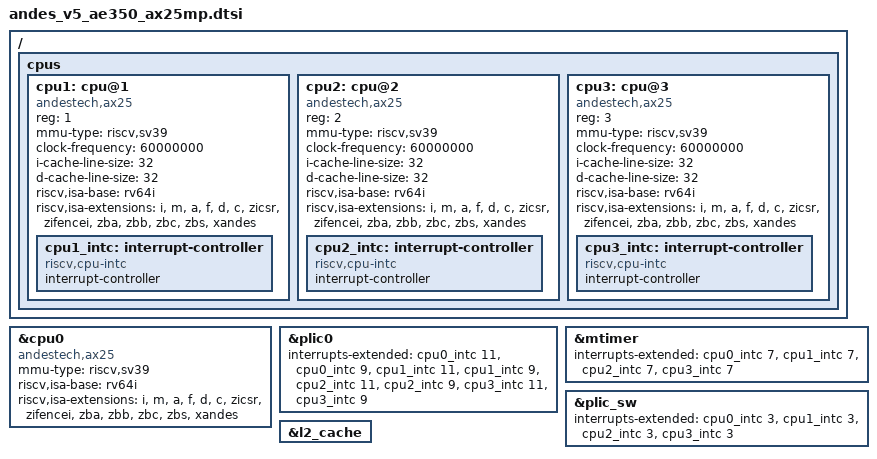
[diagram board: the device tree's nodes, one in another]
/*
 * Copyright (c) 2026 Andes Technology Corporation
 *
 * SPDX-License-Identifier: Apache-2.0
 */

#include <riscv/andes/andes_v5_ae350.dtsi>

/ {
	cpus {
		cpu1: cpu@1 {
			compatible = "andestech,ax25", "andestech,andescore-v5", "riscv";
			reg = <1>;
			device_type = "cpu";
			mmu-type = "riscv,sv39";
			clock-frequency = <60000000>;
			i-cache-line-size = <32>;
			d-cache-line-size = <32>;
			riscv,isa-base = "rv64i";
			riscv,isa-extensions = "i", "m", "a", "f", "d", "c", "zicsr", "zifencei",
					       "zba", "zbb", "zbc", "zbs", "xandes";
			status = "okay";

			cpu1_intc: interrupt-controller {
				compatible = "riscv,cpu-intc";
				#address-cells = <0>;
				#interrupt-cells = <1>;
				interrupt-controller;
			};
		};

		cpu2: cpu@2 {
			compatible = "andestech,ax25", "andestech,andescore-v5", "riscv";
			reg = <2>;
			device_type = "cpu";
			mmu-type = "riscv,sv39";
			clock-frequency = <60000000>;
			i-cache-line-size = <32>;
			d-cache-line-size = <32>;
			riscv,isa-base = "rv64i";
			riscv,isa-extensions = "i", "m", "a", "f", "d", "c", "zicsr", "zifencei",
					       "zba", "zbb", "zbc", "zbs", "xandes";
			status = "okay";

			cpu2_intc: interrupt-controller {
				compatible = "riscv,cpu-intc";
				#address-cells = <0>;
				#interrupt-cells = <1>;
				interrupt-controller;
			};
		};

		cpu3: cpu@3 {
			compatible = "andestech,ax25", "andestech,andescore-v5", "riscv";
			reg = <3>;
			device_type = "cpu";
			mmu-type = "riscv,sv39";
			clock-frequency = <60000000>;
			i-cache-line-size = <32>;
			d-cache-line-size = <32>;
			riscv,isa-base = "rv64i";
			riscv,isa-extensions = "i", "m", "a", "f", "d", "c", "zicsr", "zifencei",
					       "zba", "zbb", "zbc", "zbs", "xandes";
			status = "okay";

			cpu3_intc: interrupt-controller {
				compatible = "riscv,cpu-intc";
				#address-cells = <0>;
				#interrupt-cells = <1>;
				interrupt-controller;
			};
		};
	};
};

&cpu0 {
	compatible = "andestech,ax25", "andestech,andescore-v5", "riscv";
	mmu-type = "riscv,sv39";
	riscv,isa-base = "rv64i";
	riscv,isa-extensions = "i", "m", "a", "f", "d", "c", "zicsr", "zifencei",
			       "zba", "zbb", "zbc", "zbs", "xandes";
};

&plic0 {
	interrupts-extended = <&cpu0_intc 11 &cpu0_intc 9
			       &cpu1_intc 11 &cpu1_intc 9
			       &cpu2_intc 11 &cpu2_intc 9
			       &cpu3_intc 11 &cpu3_intc 9>;
};

&mtimer {
	interrupts-extended = <&cpu0_intc 7 &cpu1_intc 7
			       &cpu2_intc 7 &cpu3_intc 7>;
};

&plic_sw {
	interrupts-extended = <&cpu0_intc 3 &cpu1_intc 3
			       &cpu2_intc 3 &cpu3_intc 3>;
};

&l2_cache {
	status = "okay";
};
